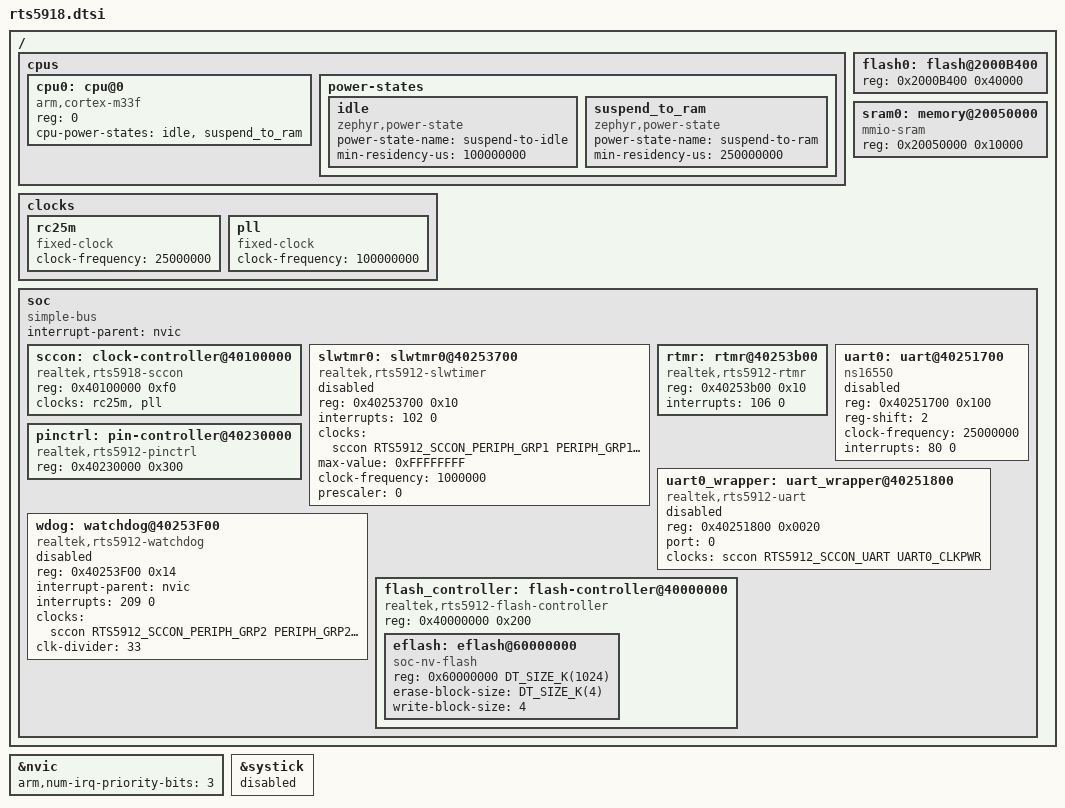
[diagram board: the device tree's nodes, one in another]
/*
 * SPDX-License-Identifier: Apache-2.0
 *
 * Copyright (c) 2024 Realtek Semiconductor Corporation, SIBG-SD7
 *
 */

#include <arm/armv8-m.dtsi>
#include <zephyr/dt-bindings/adc/adc.h>
#include <zephyr/dt-bindings/clock/rts5912_clock.h>
#include <zephyr/dt-bindings/gpio/realtek-gpio.h>
#include <zephyr/dt-bindings/pwm/pwm.h>
#include <mem.h>
#include <zephyr/dt-bindings/i2c/i2c.h>

/ {
	cpus {
		#address-cells = <1>;
		#size-cells = <0>;

		cpu0: cpu@0 {
			compatible = "arm,cortex-m33f";
			reg = <0>;
			cpu-power-states = <&idle &suspend_to_ram>;
		};

		power-states {
			idle: idle {
				compatible = "zephyr,power-state";
				power-state-name = "suspend-to-idle";
				min-residency-us = <100000000>;
			};

			suspend_to_ram: suspend_to_ram {
				compatible = "zephyr,power-state";
				power-state-name = "suspend-to-ram";
				min-residency-us = <250000000>;
			};
		};
	};

	flash0: flash@2000B400 {
		reg = <0x2000B400 0x40000>;
	};

	sram0: memory@20050000 {
		compatible = "mmio-sram";
		reg = <0x20050000 0x10000>;
	};

	clocks {
		rc25m: rc25m {
			compatible = "fixed-clock";
			clock-frequency = <25000000>;
			#clock-cells = <0>;
		};

		pll: pll {
			compatible = "fixed-clock";
			clock-frequency = <100000000>;
			#clock-cells = <0>;
		};
	};

	soc {
		#address-cells = <1>;
		#size-cells = <1>;
		compatible = "simple-bus";
		interrupt-parent = <&nvic>;
		ranges;

		sccon: clock-controller@40100000 {
			compatible = "realtek,rts5918-sccon";
			reg = <0x40100000 0xf0>;
			#clock-cells = <2>;
			clocks = <&rc25m>, <&pll>;
			clock-names = "rc25m", "pll";
		};

		slwtmr0: slwtmr0@40253700 {
			compatible = "realtek,rts5912-slwtimer";
			reg = <0x40253700 0x10>;
			interrupts = <102 0>;
			clocks = <&sccon RTS5912_SCCON_PERIPH_GRP1 PERIPH_GRP1_SLWTMR0_CLKPWR>;
			clock-names = "slwtmr";
			max-value = <0xFFFFFFFF>;
			clock-frequency = <1000000>;
			prescaler = <0>;
			status = "disabled";
		};

		rtmr: rtmr@40253b00 {
			compatible = "realtek,rts5912-rtmr";
			reg = <0x40253b00 0x10>;
			interrupts = <106 0>;
			status = "okay";
		};

		uart0: uart@40251700 {
			compatible = "ns16550";
			reg = <0x40251700 0x100>;
			reg-shift = <2>;
			clock-frequency = <25000000>;
			interrupts = <80 0>;
			status = "disabled";
		};

		uart0_wrapper: uart_wrapper@40251800 {
			compatible = "realtek,rts5912-uart";
			reg = <0x40251800 0x0020>;
			port = <0>;
			clocks = <&sccon RTS5912_SCCON_UART UART0_CLKPWR>;
			clock-names = "uart0";
			status = "disabled";
		};

		pinctrl: pin-controller@40230000 {
			compatible = "realtek,rts5912-pinctrl";
			#address-cells = <1>;
			#size-cells = <1>;
			reg = <0x40230000 0x300>;
		};

		wdog: watchdog@40253F00 {
			compatible = "realtek,rts5912-watchdog";
			reg = <0x40253F00 0x14>;
			interrupt-parent = <&nvic>;
			interrupts = <209 0>;
			clocks = <&sccon RTS5912_SCCON_PERIPH_GRP2 PERIPH_GRP2_WDT_CLKPWR>;
			clock-names = "watchdog";
			clk-divider = <33>;
			status = "disabled";
		};

		flash_controller: flash-controller@40000000 {
			compatible = "realtek,rts5912-flash-controller";
			reg = <0x40000000 0x200>;
			#address-cells = <1>;
			#size-cells = <1>;

			eflash: eflash@60000000 {
				compatible = "soc-nv-flash";
				reg = <0x60000000 DT_SIZE_K(1024)>;
				erase-block-size = <DT_SIZE_K(4)>;
				write-block-size = <4>;
			};
		};
	};
};

&nvic {
	arm,num-irq-priority-bits = <3>;
};

&systick {
	status = "disabled";
};
